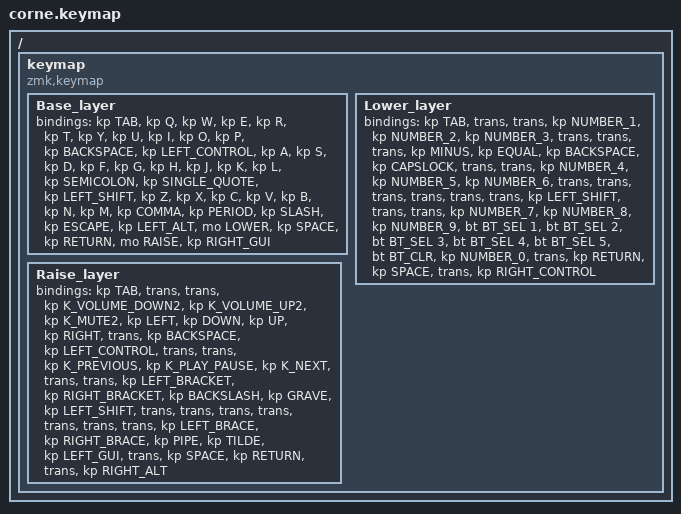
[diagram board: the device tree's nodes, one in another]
#include <behaviors.dtsi>
#include <dt-bindings/zmk/keys.h>
#include <dt-bindings/zmk/bt.h>

#define BASE 0
#define LOWER 1
#define RAISE 2

/ {
  keymap {
    compatible = "zmk,keymap";

    Base_layer {
      bindings = <
        &kp TAB &kp Q &kp W &kp E &kp R &kp T &kp Y &kp U &kp I &kp O &kp P &kp BACKSPACE &kp LEFT_CONTROL &kp A &kp S &kp D &kp F &kp G &kp H &kp J &kp K &kp L &kp SEMICOLON &kp SINGLE_QUOTE &kp LEFT_SHIFT &kp Z &kp X &kp C &kp V &kp B &kp N &kp M &kp COMMA &kp PERIOD &kp SLASH &kp ESCAPE &kp LEFT_ALT &mo LOWER &kp SPACE &kp RETURN &mo RAISE &kp RIGHT_GUI 
      >;
    };

    Lower_layer {
      bindings = <
        &kp TAB &trans &trans &kp NUMBER_1 &kp NUMBER_2 &kp NUMBER_3 &trans &trans &trans &kp MINUS &kp EQUAL &kp BACKSPACE &kp CAPSLOCK &trans &trans &kp NUMBER_4 &kp NUMBER_5 &kp NUMBER_6 &trans &trans &trans &trans &trans &trans &kp LEFT_SHIFT &trans &trans &kp NUMBER_7 &kp NUMBER_8 &kp NUMBER_9 &bt BT_SEL 1 &bt BT_SEL 2 &bt BT_SEL 3 &bt BT_SEL 4 &bt BT_SEL 5 &bt BT_CLR &kp NUMBER_0 &trans &kp RETURN &kp SPACE &trans &kp RIGHT_CONTROL 
      >;
    };

    Raise_layer {
      bindings = <
        &kp TAB &trans &trans &kp K_VOLUME_DOWN2 &kp K_VOLUME_UP2 &kp K_MUTE2 &kp LEFT &kp DOWN &kp UP &kp RIGHT &trans &kp BACKSPACE &kp LEFT_CONTROL &trans &trans &kp K_PREVIOUS &kp K_PLAY_PAUSE &kp K_NEXT &trans &trans &kp LEFT_BRACKET &kp RIGHT_BRACKET &kp BACKSLASH &kp GRAVE &kp LEFT_SHIFT &trans &trans &trans &trans &trans &trans &trans &kp LEFT_BRACE &kp RIGHT_BRACE &kp PIPE &kp TILDE &kp LEFT_GUI &trans &kp SPACE &kp RETURN &trans &kp RIGHT_ALT 
      >;
    };

  };
};
